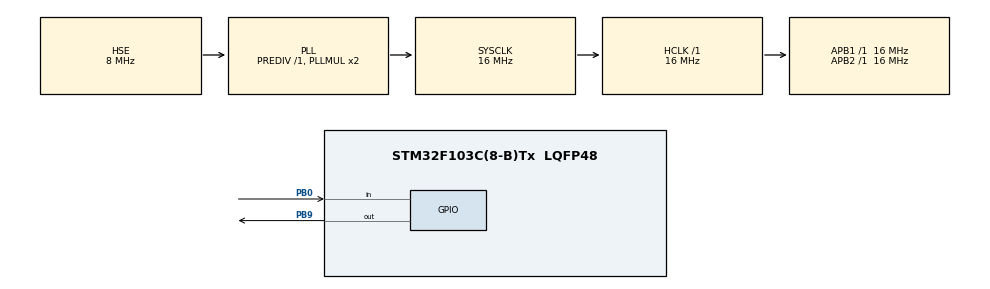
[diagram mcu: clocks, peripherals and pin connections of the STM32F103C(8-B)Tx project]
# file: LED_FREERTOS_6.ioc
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FREERTOS.Tasks01=defaultTask,24,128,StartDefaultTask,Default,NULL,Dynamic,NULL,NULL
Mcu.Family=STM32F1
Mcu.Name=STM32F103C(8-B)Tx
Mcu.Package=LQFP48
NVIC.PriorityGroup=NVIC_PRIORITYGROUP_4
NVIC.TIM1_UP_IRQn=true\:0\:0\:false\:false\:true\:false\:false\:true\:true
NVIC.TimeBase=TIM1_UP_IRQn
NVIC.TimeBaseIP=TIM1
PA13.Mode=Serial_Wire
PA13.Signal=SYS_JTMS-SWDIO
PA14.Mode=Serial_Wire
PA14.Signal=SYS_JTCK-SWCLK
PB0.GPIO_PuPd=GPIO_PULLUP
PB0.Signal=GPIO_Input
PB9.Signal=GPIO_Output
PD0-OSC_IN.Mode=HSE-External-Oscillator
PD0-OSC_IN.Signal=RCC_OSC_IN
PD1-OSC_OUT.Mode=HSE-External-Oscillator
PD1-OSC_OUT.Signal=RCC_OSC_OUT
ProjectManager.HeapSize=0x200
ProjectManager.StackSize=0x400
ProjectManager.TargetToolchain=STM32CubeIDE
RCC.AHBFreq_Value=16000000
RCC.APB1Freq_Value=16000000
RCC.APB1TimFreq_Value=16000000
RCC.APB2Freq_Value=16000000
RCC.APB2TimFreq_Value=16000000
RCC.HCLKFreq_Value=16000000
RCC.PLLSourceVirtual=RCC_PLLSOURCE_HSE
RCC.SYSCLKFreq_VALUE=16000000
RCC.SYSCLKSource=RCC_SYSCLKSOURCE_PLLCLK
RCC.USBFreq_Value=16000000
VP_FREERTOS_VS_CMSIS_V2.Mode=CMSIS_V2
VP_SYS_VS_tim1.Mode=TIM1
board=custom

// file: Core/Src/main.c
/* USER CODE BEGIN Header */
/**
  ******************************************************************************
  * @file           : main.c
  * @brief          : Main program body
  ******************************************************************************
  * @attention
  *
  * <h2><center>&copy; Copyright (c) 2022 STMicroelectronics.
  * All rights reserved.</center></h2>
  *
  * This software component is licensed by ST under Ultimate Liberty license
  * SLA0044, the "License"; You may not use this file except in compliance with
  * the License. You may obtain a copy of the License at:
  *                             www.st.com/SLA0044
  *
  ******************************************************************************
  */
/* USER CODE END Header */
#include "main.h"
#include "cmsis_os.h"
#include "arrebote.h"
#include "task.h"
#include "semphr.h"

/* USER CODE BEGIN Includes */
#define DEBOUNCE_BTN_MS	(20)
#define FALSE			(0)
#define TRUE			(!FALSE)
/* USER CODE END Includes */

/* Definitions for defaultTask */
osThreadId_t defaultTaskHandle;
const osThreadAttr_t defaultTask_attributes = {
  .name = "defaultTask",
  .priority = (osPriority_t) osPriorityNormal,
  .stack_size = 128 * 4
};

void SystemClock_Config(void);
static void MX_GPIO_Init(void);
void StartDefaultTask(void *argument);

/* USER CODE BEGIN PFP */
void tarea_led(void* p);
void tarea_pulsador(void* p);
/* USER CODE END PFP */

xSemaphoreHandle sem_led;
uint32_t tiempo_ms = 0;
arrebote boton_b1;

int main(void)
{

  /* MCU Configuration--------------------------------------------------------*/

  /* Reset of all peripherals, Initializes the Flash interface and the Systick. */
  HAL_Init();

  /* Configure the system clock */
  SystemClock_Config();

  /* Initialize all configured peripherals */
  MX_GPIO_Init();

  /* Init scheduler */
  osKernelInitialize();

  xTaskCreate(	tarea_pulsador,
		  	  	"tarea pulsador",
				configMINIMAL_STACK_SIZE,
				NULL,
				tskIDLE_PRIORITY+1,
				NULL);

  xTaskCreate(	tarea_led,
		  	  	"tarea led",
				configMINIMAL_STACK_SIZE*2,
				NULL,
				tskIDLE_PRIORITY+1,
				NULL);

  vSemaphoreCreateBinary(sem_led);

  xSemaphoreTake(sem_led, portMAX_DELAY);//tomo el semaforo antes de iniciar las tareas
  /* Start scheduler */
  osKernelStart();

  /* We should never get here as control is now taken by the scheduler */
  /* Infinite loop */
  while (1)
  {

  }
}

void tarea_led(void* p){

	for(;;){

		if(xSemaphoreTake(sem_led, portMAX_DELAY) == pdTRUE){

			HAL_GPIO_TogglePin(GPIOB, GPIO_PIN_9);
			vTaskDelay(tiempo_ms);
		}
	}
}

void tarea_pulsador(void* p){

	static uint32_t estado_boton = 0;
	uint32_t tics_led;
	uint8_t flag_sem = 0;

	inicializar_arrebote(&boton_b1, TRUE, DEBOUNCE_BTN_MS);

	for(;;)
	{
		chequear_arrebote(&boton_b1, HAL_GPIO_ReadPin(GPIOB, GPIO_PIN_0));//ES ACTIVO EN CERO
		if(hay_flanco_arrebote(&boton_b1))
		{
			estado_boton^=1;//cambio el estado del boton
			if(estado_boton == 1){//si es 1 quiere decir que se presiono el boton

				tics_led = xTaskGetTickCount();

			}
			else{//se solto el boton

				tics_led = xTaskGetTickCount() - tics_led;//la cantidad de ticks se calcula haciendo la resta
				tiempo_ms = tics_led/portTICK_RATE_MS;
				if(tiempo_ms < 50) tiempo_ms = 50;
				else if(tiempo_ms > 1000) tiempo_ms = 1000;
				flag_sem = 1;//esto permite devolver el semaforo la primera vez que se presiona el boton
			}

		}

		if(flag_sem){

			xSemaphoreGive(sem_led);//devuelvo el semaforo
			vTaskDelay(1/portTICK_RATE_MS);
		}
	}
}

void SystemClock_Config(void)
{
  RCC_OscInitTypeDef RCC_OscInitStruct = {0};
  RCC_ClkInitTypeDef RCC_ClkInitStruct = {0};

  /** Initializes the RCC Oscillators according to the specified parameters
  * in the RCC_OscInitTypeDef structure.
  */
  RCC_OscInitStruct.OscillatorType = RCC_OSCILLATORTYPE_HSE;
  RCC_OscInitStruct.HSEState = RCC_HSE_ON;
  RCC_OscInitStruct.HSEPredivValue = RCC_HSE_PREDIV_DIV1;
  RCC_OscInitStruct.HSIState = RCC_HSI_ON;
  RCC_OscInitStruct.PLL.PLLState = RCC_PLL_ON;
  RCC_OscInitStruct.PLL.PLLSource = RCC_PLLSOURCE_HSE;
  RCC_OscInitStruct.PLL.PLLMUL = RCC_PLL_MUL2;
  if (HAL_RCC_OscConfig(&RCC_OscInitStruct) != HAL_OK)
  {
    Error_Handler();
  }
  /** Initializes the CPU, AHB and APB buses clocks
  */
  RCC_ClkInitStruct.ClockType = RCC_CLOCKTYPE_HCLK|RCC_CLOCKTYPE_SYSCLK
                              |RCC_CLOCKTYPE_PCLK1|RCC_CLOCKTYPE_PCLK2;
  RCC_ClkInitStruct.SYSCLKSource = RCC_SYSCLKSOURCE_PLLCLK;
  RCC_ClkInitStruct.AHBCLKDivider = RCC_SYSCLK_DIV1;
  RCC_ClkInitStruct.APB1CLKDivider = RCC_HCLK_DIV1;
  RCC_ClkInitStruct.APB2CLKDivider = RCC_HCLK_DIV1;

  if (HAL_RCC_ClockConfig(&RCC_ClkInitStruct, FLASH_LATENCY_0) != HAL_OK)
  {
    Error_Handler();
  }
}

static void MX_GPIO_Init(void)
{
  GPIO_InitTypeDef GPIO_InitStruct = {0};

  /* GPIO Ports Clock Enable */
  __HAL_RCC_GPIOD_CLK_ENABLE();
  __HAL_RCC_GPIOB_CLK_ENABLE();
  __HAL_RCC_GPIOA_CLK_ENABLE();

  /*Configure GPIO pin Output Level */
  HAL_GPIO_WritePin(GPIOB, GPIO_PIN_9, GPIO_PIN_RESET);

  /*Configure GPIO pin : PB0 */
  GPIO_InitStruct.Pin = GPIO_PIN_0;
  GPIO_InitStruct.Mode = GPIO_MODE_INPUT;
  GPIO_InitStruct.Pull = GPIO_PULLUP;
  HAL_GPIO_Init(GPIOB, &GPIO_InitStruct);

  /*Configure GPIO pin : PB9 */
  GPIO_InitStruct.Pin = GPIO_PIN_9;
  GPIO_InitStruct.Mode = GPIO_MODE_OUTPUT_PP;
  GPIO_InitStruct.Pull = GPIO_NOPULL;
  GPIO_InitStruct.Speed = GPIO_SPEED_FREQ_LOW;
  HAL_GPIO_Init(GPIOB, &GPIO_InitStruct);

}

void StartDefaultTask(void *argument)
{
  for(;;)
  {
    osDelay(1);
  }
}

void HAL_TIM_PeriodElapsedCallback(TIM_HandleTypeDef *htim)
{
  if (htim->Instance == TIM1) {
    HAL_IncTick();
  }
}

void Error_Handler(void)
{
}

/************************ (C) COPYRIGHT STMicroelectronics *****END OF FILE****/
